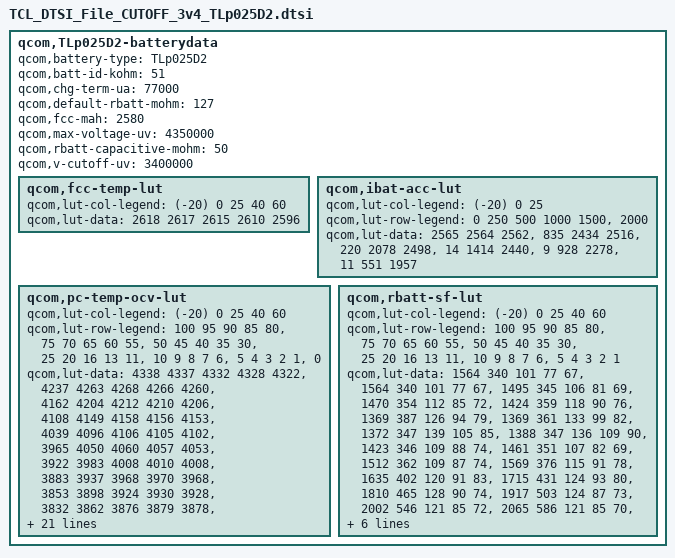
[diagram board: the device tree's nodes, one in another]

qcom,TLp025D2-batterydata {
	qcom,battery-type = "TLp025D2";
	qcom,batt-id-kohm = <51>;
	qcom,chg-term-ua = <77000>;
	qcom,default-rbatt-mohm = <127>;
	qcom,fcc-mah = <2580>;
	qcom,max-voltage-uv = <4350000>;
	qcom,rbatt-capacitive-mohm = <50>;
	qcom,v-cutoff-uv = <3400000>;

	qcom,fcc-temp-lut {
		qcom,lut-col-legend = <(-20) 0 25 40 60>;
		qcom,lut-data = <2618 2617 2615 2610 2596>;
	};

	qcom,ibat-acc-lut {
		qcom,lut-col-legend = <(-20) 0 25>;
		qcom,lut-row-legend = <0 250 500 1000 1500>,
					<2000>;
		qcom,lut-data = <2565 2564 2562>,
				<835 2434 2516>,
				<220 2078 2498>,
				<14 1414 2440>,
				<9 928 2278>,
				<11 551 1957>;
	};

	qcom,pc-temp-ocv-lut {
		qcom,lut-col-legend = <(-20) 0 25 40 60>;
		qcom,lut-row-legend = <100 95 90 85 80>,
					<75 70 65 60 55>,
					<50 45 40 35 30>,
					<25 20 16 13 11>,
					<10 9 8 7 6>,
					<5 4 3 2 1>,
					<0>;
		qcom,lut-data = <4338 4337 4332 4328 4322>,
				<4237 4263 4268 4266 4260>,
				<4162 4204 4212 4210 4206>,
				<4108 4149 4158 4156 4153>,
				<4039 4096 4106 4105 4102>,
				<3965 4050 4060 4057 4053>,
				<3922 3983 4008 4010 4008>,
				<3883 3937 3968 3970 3968>,
				<3853 3898 3924 3930 3928>,
				<3832 3862 3876 3879 3878>,
				<3814 3833 3844 3845 3845>,
				<3798 3809 3820 3822 3821>,
				<3782 3791 3801 3802 3801>,
				<3765 3778 3784 3784 3784>,
				<3748 3764 3770 3768 3763>,
				<3729 3748 3758 3750 3738>,
				<3706 3729 3735 3726 3714>,
				<3686 3712 3705 3698 3685>,
				<3666 3698 3688 3680 3668>,
				<3652 3690 3684 3676 3666>,
				<3642 3685 3682 3676 3664>,
				<3632 3680 3680 3674 3662>,
				<3619 3674 3678 3672 3660>,
				<3604 3666 3672 3665 3652>,
				<3586 3650 3656 3646 3628>,
				<3562 3623 3618 3606 3588>,
				<3528 3580 3566 3556 3537>,
				<3480 3518 3500 3491 3472>,
				<3406 3430 3412 3404 3382>,
				<3282 3296 3272 3268 3245>,
				<3000 3000 3000 3003 3000>;
	};

	qcom,rbatt-sf-lut {
		qcom,lut-col-legend = <(-20) 0 25 40 60>;
		qcom,lut-row-legend = <100 95 90 85 80>,
					<75 70 65 60 55>,
					<50 45 40 35 30>,
					<25 20 16 13 11>,
					<10 9 8 7 6>,
					<5 4 3 2 1>;
		qcom,lut-data = <1564 340 101 77 67>,
				<1564 340 101 77 67>,
				<1495 345 106 81 69>,
				<1470 354 112 85 72>,
				<1424 359 118 90 76>,
				<1369 387 126 94 79>,
				<1369 361 133 99 82>,
				<1372 347 139 105 85>,
				<1388 347 136 109 90>,
				<1423 346 109 88 74>,
				<1461 351 107 82 69>,
				<1512 362 109 87 74>,
				<1569 376 115 91 78>,
				<1635 402 120 91 83>,
				<1715 431 124 93 80>,
				<1810 465 128 90 74>,
				<1917 503 124 87 73>,
				<2002 546 121 85 72>,
				<2065 586 121 85 70>,
				<1958 585 127 90 76>,
				<2046 603 132 94 77>,
				<2175 623 139 98 78>,
				<2339 647 145 101 80>,
				<2539 668 150 102 78>,
				<2790 689 149 97 76>,
				<3109 709 142 94 77>,
				<3531 731 147 99 80>,
				<4155 768 157 104 83>,
				<5169 822 172 114 87>,
				<7511 956 217 136 106>;
	};
};
/* TEST_DB_ID=TEST_ID_NOT_SET */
